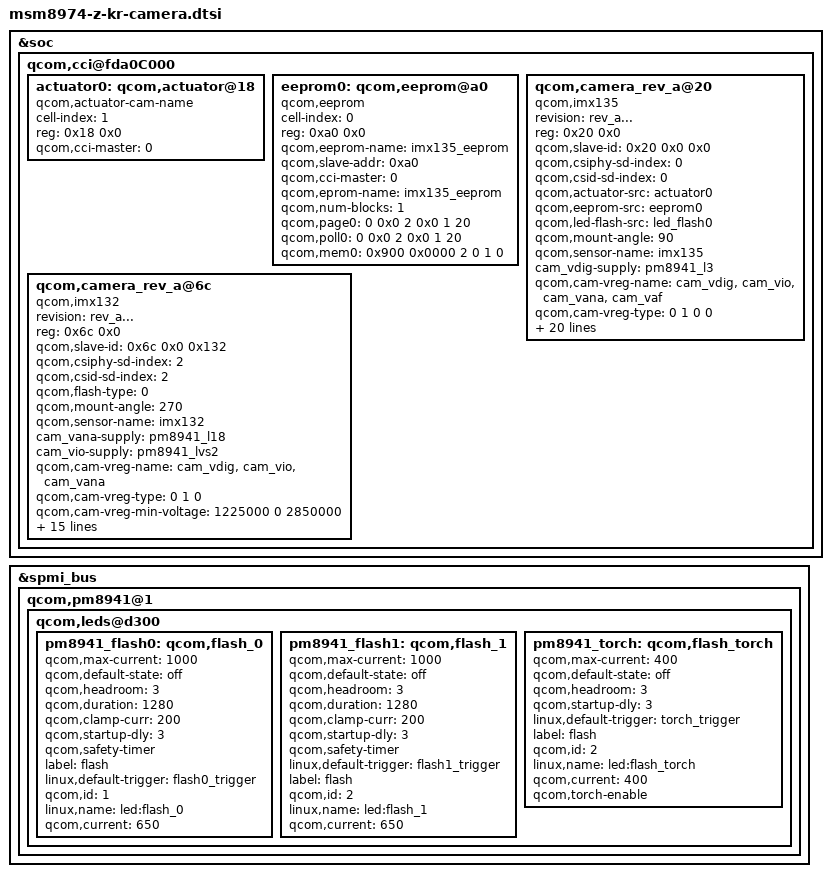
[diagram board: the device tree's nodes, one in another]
/*
 * Copyright (c) 2012, The Linux Foundation. All rights reserved.
 *
 * This program is free software; you can redistribute it and/or modify
 * it under the terms of the GNU General Public License version 2 and
 * only version 2 as published by the Free Software Foundation.
 *
 * This program is distributed in the hope that it will be useful,
 * but WITHOUT ANY WARRANTY; without even the implied warranty of
 * MERCHANTABILITY or FITNESS FOR A PARTICULAR PURPOSE.  See the
 * GNU General Public License for more details.
 */

/include/ "../skeleton.dtsi"

&soc {
	qcom,cci@fda0C000 {
		actuator0: qcom,actuator@18 {
			cell-index = <1>;//Use Af_main_1 of dw9714
			reg = <0x18 0x0>;
			compatible = "qcom,actuator-cam-name"; //CS migration
			qcom,cci-master = <0>;
		};

		eeprom0: qcom,eeprom@a0 { //EEPROM READ
			cell-index = <0>;
			reg = <0xa0 0x0>;
			qcom,eeprom-name = "imx135_eeprom";
			compatible = "qcom,eeprom";
			qcom,slave-addr = <0xa0>;
			qcom,cci-master = <0>;
			qcom,eprom-name = "imx135_eeprom";
			qcom,num-blocks = <1>;
			qcom,page0 = <0 0x0 2 0x0 1 20>;
			qcom,poll0 = <0 0x0 2 0x0 1 20>;
			qcom,mem0 = <0x900 0x0000 2 0 1 0>; //EEPROM READ
		};

		qcom,camera_rev_a@20 {
			status = "ok";
			compatible = "qcom,imx135";
			revision = "rev_a...";
			reg = <0x20 0x0>;
			qcom,slave-id = <0x20 0x0 0x0>;
			qcom,csiphy-sd-index = <0>;
			qcom,csid-sd-index = <0>;
			qcom,actuator-src = <&actuator0>;
			qcom,eeprom-src = <&eeprom0>; //Read EEPROM
			qcom,led-flash-src = <&led_flash0>;
			qcom,mount-angle = <90>;
			qcom,sensor-name = "imx135";
			cam_vdig-supply = <&pm8941_l3>;
			qcom,cam-vreg-name = "cam_vdig", "cam_vio", "cam_vana", "cam_vaf";
			qcom,cam-vreg-type = <0 1 0 0 >;
			// Need to be changed the AF setting value as LGIT module: 1.8V, Sony module: 2.8V
			qcom,cam-vreg-min-voltage = <1225000 0 0 1800000>;
			qcom,cam-vreg-max-voltage = <1225000 0 0 1800000>;
			qcom,cam-vreg-op-mode = <105000 0 0 100000>;
			qcom,gpio-no-mux = <0>;
			// MAIN_CAM_MCLK, Need to be set as 24MHz, 19.2MHz is set temporarily.
			gpios = <&msmgpio 15 0>, 		// MCLK
				<&msmgpio 4 0>,			// MAIN_CAM_RESET
				<&msmgpio 16 0>,		// 13M_VANA_EN
				<&msmgpio 96 0>,		// 13M_VIO_EN
				<&msmgpio 57 0>;		// 13M_VCM_EN
			qcom,gpio-reset = <1>; 		// Set gpio_4 as reset
			qcom,gpio-vana = <2>;		// Set gpio_16 as VANA
			qcom,gpio-vio = <3>;		// Set gpio_96 as VIO
			qcom,gpio-vcm = <4>;		// Set gpio_57 as VCM
			qcom,gpio-req-tbl-num = <0 1 2 3 4>;
			qcom,gpio-req-tbl-flags = <0 0 0 0 0>;
			qcom,gpio-req-tbl-label =  "CAMIF_MCLK", "CAM_RESET1", "MAIN_VANA_EN", "MAIN_VIO_EN", "MAIN_VCM_EN";
			qcom,csi-lane-assign = <0x4320>;
			qcom,csi-lane-mask = <0x1F>;
			qcom,sensor-position = <0>;
			qcom,sensor-mode = <0>;
			qcom,cci-master = <0>;
		};

		qcom,camera_rev_a@6c {
			status = "ok";
			compatible = "qcom,imx132";
			revision = "rev_a...";
			reg = <0x6c 0x0>;
			qcom,slave-id = <0x6c 0x0 0x132>;
			qcom,csiphy-sd-index = <2>;
			qcom,csid-sd-index = <2>;
			qcom,flash-type = <0>;
			qcom,mount-angle = <270>;
			qcom,sensor-name = "imx132";
			cam_vana-supply = <&pm8941_l18>;
			cam_vio-supply = <&pm8941_lvs2>;
			qcom,cam-vreg-name = "cam_vdig", "cam_vio", "cam_vana";
			qcom,cam-vreg-type = <0 1 0>;
			qcom,cam-vreg-min-voltage = <1225000 0 2850000>;
			qcom,cam-vreg-max-voltage = <1225000 0 2850000>;
			qcom,cam-vreg-op-mode = <105000 0 80000>;
			qcom,gpio-no-mux = <0>;
			gpios = <&msmgpio 17 0>, //VT_CAM_MCLK
				<&msmgpio 18 0>, //VT_CAM_RESET
				<&msmgpio 30 0>; //VT_LDO_EN
			qcom,gpio-reset = <1>;
			qcom,gpio-vdig = <2>;
			qcom,gpio-req-tbl-num = <0 1 2>;
			qcom,gpio-req-tbl-flags = <0 0 0>;
			qcom,gpio-req-tbl-label = "CAMIF_MCLK2",
						     "CAM_RESET2",
						     "VT_LDO_EN";
			qcom,csi-lane-assign = <0x4320>;
			qcom,csi-lane-mask = <0x3>;
			qcom,sensor-position = <1>;
			qcom,sensor-mode = <1>;
			qcom,cci-master = <1>;
		};
	};
};

&spmi_bus {
	qcom,pm8941@1 {
		qcom,leds@d300 {
			status = "okay";
			pm8941_flash0: qcom,flash_0 {
				qcom,max-current = <1000>;
				qcom,default-state = "off";
				qcom,headroom = <3>;
				qcom,duration = <1280>;
				qcom,clamp-curr = <200>;
				qcom,startup-dly = <3>;
				qcom,safety-timer;
				label = "flash";
				linux,default-trigger =
					"flash0_trigger";
				qcom,id = <1>;
				linux,name = "led:flash_0";
				qcom,current = <650>;
			};

			pm8941_flash1: qcom,flash_1 {
				qcom,max-current = <1000>;
				qcom,default-state = "off";
				qcom,headroom = <3>;
				qcom,duration = <1280>;
				qcom,clamp-curr = <200>;
				qcom,startup-dly = <3>;
				qcom,safety-timer;
				linux,default-trigger =
					"flash1_trigger";
				label = "flash";
				qcom,id = <2>;
				linux,name = "led:flash_1";
				qcom,current = <650>;
			};

			pm8941_torch: qcom,flash_torch {
				qcom,max-current = <400>;
				qcom,default-state = "off";
				qcom,headroom = <3>;
				qcom,startup-dly = <3>;
				linux,default-trigger =
					"torch_trigger";
				label = "flash";
				qcom,id = <2>;
				linux,name = "led:flash_torch";
				qcom,current = <400>;
				qcom,torch-enable;
			};
		};
	};
};
